# MSPM0C1106 register map
Vendor: Texas Instruments; File version: Revised: 2025-01-26 23:02:57
ARM Device
CPU: CM0 r0p1, little endian, MPU, no FPU, 3 interrupt priority bits
Registers are 32-bit, read-write, reset 0x0 unless marked. A register's access mark holds for its fields unless they carry their own. Offsets are from the block's base; lines under a group give offsets from that group; [hi:lo] are bit positions; {n}, {i} and the like mark numbered series; 'fields as' and 'values as' point back to an identical list; <NAME> marks a mode.

## Memory map
0x00000000 FLASH size 0x10000 — MEM
0x20000000 SYSMEM size 0x2000 — MEM
0x40004000 ADC0 size 0x2000 — PERIPHERALREGION
0x40008000 COMP0 size 0x1F00 — PERIPHERALREGION
0x40030000 VREF size 0x1F00 — PERIPHERALREGION
0x40080000 WWDT0 size 0x1500 — WWDT
0x40084000 TIMG14 size 0x1F00 — PERIPHERALREGION
0x40086000 TIMG1 size 0x1F00 — PERIPHERALREGION
0x40088000 TIMG2 size 0x1F00 — PERIPHERALREGION
0x40090000 TIMG8 size 0x1F00 — PERIPHERALREGION
0x40094000 LFSS size 0x1600 — PERIPHERALREGION
0x400A0000 GPIOA size 0x1F00 — PERIPHERALREGION
0x400A2000 GPIOB size 0x1F00 — PERIPHERALREGION
0x400AF000 SYSCTL size 0x3100 — mem_map
0x400C7000 DEBUGSS size 0x1F00 — DSSM
0x400C9000 EVENTLP size 0x3000 — PERIPHERALREGION
0x400CD000 FLASHCTL size 0x2000 — NVMNW_N148
0x400F0000 I2C0 size 0x1F00 — PERIPHERALREGION
0x400F2000 I2C1 size 0x1F00 — PERIPHERALREGION
0x40100000 UART1 size 0x1F00 — PERIPHERALREGION
0x40102000 UART2 size 0x1F00 — PERIPHERALREGION
0x40108000 UART0 size 0x1F00 — PERIPHERALREGION
0x40400000 CPUSS size 0x1F00 — CPUSSMMR
0x40424000 WUC size 0x500 — PERIPHERALREGION
0x40428000 IOMUX size 0x2000 — PERIPHERALREGION
0x4042A000 DMA size 0x1F00 — PERIPHERALREGION
0x40440000 CRC size 0x2000 — PERIPHERALREGION
0x40468000 SPI0 size 0x1F00 — PERIPHERALREGION
0x4055A000 ADC0_SVT size 0x1000 — PERIPHERALREGIONSVT
0x40860000 TIMA0 size 0x1F00 — PERIPHERALREGION

## CRC — PERIPHERALREGION
Base 0x40440000
{0x800+0x18*i} CRC_GPRCM[{i}] (i=0..0) group
  0x00 CRC_PWREN — Power enable
    [0] ENABLE — Enable the power
      0=DISABLE (Disable Power); 1=ENABLE (Enable Power)
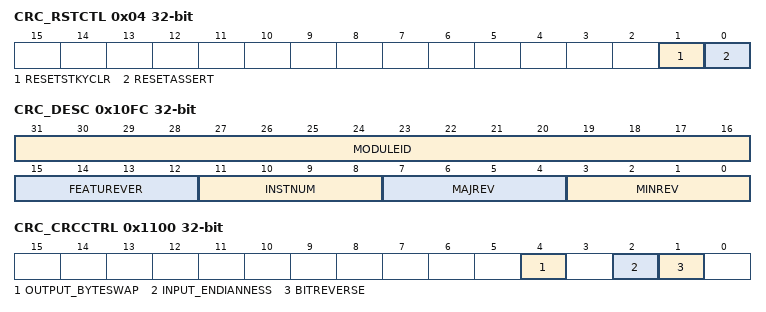
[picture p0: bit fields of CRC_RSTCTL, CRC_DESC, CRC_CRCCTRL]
  0x04 CRC_RSTCTL wo — Reset Control
    [1] RESETSTKYCLR — Clear the RESETSTKY bit in the STAT register
      0=NOP (Writing 0 has no effect); 1=CLR (Clear reset sticky bit)
    [0] RESETASSERT — Assert reset to the peripheral
      0=NOP (Writing 0 has no effect); 1=ASSERT (Assert reset)
  0x14 CRC_STAT ro — Status Register
    [16] RESETSTKY — This bit indicates, if the peripheral was reset, since this bit was cleared by RESETSTKYCLR in the RSTCTL register
      0=NORES (The peripheral has not been reset since this bit was last cleared by RESETSTKYCLR in the RSTCTL register); 1=RESET (The peripheral was reset since the last bit clear)
0x10FC CRC_DESC ro — Module Description
  [31:16] MODULEID — Module identification contains a unique peripheral identification number. The assignments are maintained in a central database for all of the platform modules to ensure uniqueness.
  [15:12] FEATUREVER — Feature Set for the module *instance*
  [11:8] INSTNUM — Instance Number within the device. This will be a parameter to the RTL for modules that can have multiple instances
  [7:4] MAJREV — Major rev of the IP
  [3:0] MINREV — Minor rev of the IP
0x1100 CRC_CRCCTRL — CRC Control Register
  [4] OUTPUT_BYTESWAP — CRC Output Byteswap Enable. This bit controls whether the output is byte-swapped upon a read of the CRCOUT register. If CRCOUT is accessed as a half-word, and the OUTPUT_BYTESWAP is set to to 1, then the two bytes in the 16-bit access are swapped and returned. B1 is returned as B0 B0 is returned as B1 If CRCOUT is accessed as a word, and the OUTPUT_BYTESWAP is set to 1, then the four bytes in the 32-bit read are swapped. B3 is returned as B0 B2 is returned as B1 B1 is returned as B2 B0 is returned as B3 Note that if the CRC POLYSIZE is 16-bit and a 32-bit read of CRCOUT is performed with OUTPUT_BYTESWAP enabled, then the output is: MSB LSB 0x0 0x0 B0 B1 If the CRC POLYSIZE is 16-bit and a 32-bit read of CRCOUT is performed with OUTPUT_BYTESWAP disabled, then the output is: MSB LSB 0x0 0x0 B1 B0
    0=DISABLE (Output byteswapping is disabled); 1=ENABLE (Output byteswapping is enabled.)
  [2] INPUT_ENDIANNESS — CRC Endian. This bit indicates the byte order within a word or half word of input data.
    0=LITTLE_ENDIAN (LSB is lowest memory address and first to be processed.); 1=BIG_ENDIAN (LSB is highest memory address and last to be processed.)
  [1] BITREVERSE — CRC Bit Input and output Reverse. This bit indicates that the bit order of each input byte used for the CRC calculation is reversed before it is passed to the generator, and that the bit order of the calculated CRC is be reversed when read from CRC_RESULT.
    0=NOT_REVERSED (Bit order is not reversed.); 1=REVERSED (Bit order is reversed.)
0x1104 CRC_CRCSEED wo — CRC Seed Register
  [31:0] SEED — Seed Data
0x1108 CRC_CRCIN wo — CRC Input Data Register
  [31:0] DATA — Input Data
0x110C CRC_CRCOUT ro — CRC Output Result Register
  [31:0] RESULT
{0x1800+4i} CRC_CRCIN_IDX[{i}] (i=0..511) wo — CRC Input Data Array Register
  [31:0] DATA — Input Data

## Licence text in the file
Copyright (C) 2025 Texas Instruments Incorporated - http://www.ti.com/ Redistribution and use in source and binary forms, with or without modification, are permitted provided that the following conditions are met: Redistributions of source code must retain the above copyright notice, this list of conditions and the following disclaimer. Redistributions in binary form must reproduce the above copyright notice, this list of conditions and the following disclaimer in the documentation and/or other materials provided with the distribution. Neither the name of Texas Instruments Incorporated nor the names of its contributors may be used to endorse or promote products derived from this software without specific prior written permission. THIS SOFTWARE IS PROVIDED BY THE COPYRIGHT HOLDERS AND CONTRIBUTORS "AS IS" AND ANY EXPRESS OR IMPLIED WARRANTIES, INCLUDING, BUT NOT LIMITED TO, THE IMPLIED WARRANTIES OF MERCHANTABILITY AND FITNESS FOR A PARTICULAR PURPOSE ARE DISCLAIMED. IN NO EVENT SHALL THE COPYRIGHT OWNER OR CONTRIBUTORS BE LIABLE FOR ANY DIRECT, INDIRECT, INCIDENTAL, SPECIAL, EXEMPLARY, OR CONSEQUENTIAL DAMAGES (INCLUDING, BUT NOT LIMITED TO, PROCUREMENT OF SUBSTITUTE GOODS OR SERVICES; LOSS OF USE, DATA, OR PROFITS; OR BUSINESS INTERRUPTION) HOWEVER CAUSED AND ON ANY THEORY OF LIABILITY, WHETHER IN CONTRACT, STRICT LIABILITY, OR TORT (INCLUDING NEGLIGENCE OR OTHERWISE) ARISING IN ANY WAY OUT OF THE USE OF THIS SOFTWARE, EVEN IF ADVISED OF THE POSSIBILITY OF SUCH DAMAGE.
